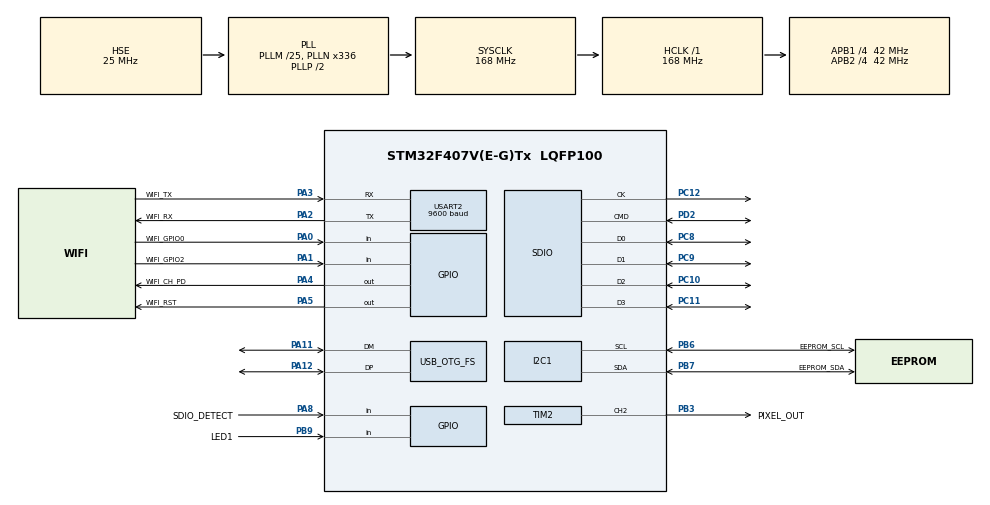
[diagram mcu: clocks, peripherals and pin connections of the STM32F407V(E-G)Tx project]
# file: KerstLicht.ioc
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Dma.Request0=TIM2_CH2/CH4
Dma.Request1=USART2_RX
Dma.TIM2_CH2/CH4.0.Direction=DMA_MEMORY_TO_PERIPH
Dma.TIM2_CH2/CH4.0.FIFOMode=DMA_FIFOMODE_DISABLE
Dma.TIM2_CH2/CH4.0.Instance=DMA1_Stream6
Dma.TIM2_CH2/CH4.0.MemDataAlignment=DMA_MDATAALIGN_WORD
Dma.TIM2_CH2/CH4.0.MemInc=DMA_MINC_ENABLE
Dma.TIM2_CH2/CH4.0.Mode=DMA_NORMAL
Dma.TIM2_CH2/CH4.0.PeriphDataAlignment=DMA_PDATAALIGN_WORD
Dma.TIM2_CH2/CH4.0.PeriphInc=DMA_PINC_DISABLE
Dma.TIM2_CH2/CH4.0.Priority=DMA_PRIORITY_HIGH
Dma.USART2_RX.1.Direction=DMA_PERIPH_TO_MEMORY
Dma.USART2_RX.1.FIFOMode=DMA_FIFOMODE_ENABLE
Dma.USART2_RX.1.FIFOThreshold=DMA_FIFO_THRESHOLD_FULL
Dma.USART2_RX.1.Instance=DMA1_Stream5
Dma.USART2_RX.1.MemBurst=DMA_MBURST_SINGLE
Dma.USART2_RX.1.MemDataAlignment=DMA_MDATAALIGN_BYTE
Dma.USART2_RX.1.MemInc=DMA_MINC_ENABLE
Dma.USART2_RX.1.Mode=DMA_NORMAL
Dma.USART2_RX.1.PeriphBurst=DMA_PBURST_SINGLE
Dma.USART2_RX.1.PeriphDataAlignment=DMA_PDATAALIGN_BYTE
Dma.USART2_RX.1.PeriphInc=DMA_PINC_DISABLE
Dma.USART2_RX.1.Priority=DMA_PRIORITY_LOW
FATFS.BSP.number=1
FATFS.USE_DMA_CODE_SD=1
FATFS0.BSP.STBoard=false
FATFS0.BSP.api=Unknown
FATFS0.BSP.i2caddr=0
FATFS0.BSP.instance=PA8
FATFS0.BSP.ip=GPIO
FATFS0.BSP.mode=Input
FATFS0.BSP.name=Detect_SDIO
FATFS0.BSP.solution=PA8
FREERTOS.Tasks01=defaultTask,0,128,StartDefaultTask,Default,NULL,Dynamic,NULL,NULL
Mcu.Family=STM32F4
Mcu.Name=STM32F407V(E-G)Tx
Mcu.Package=LQFP100
NVIC.DMA1_Stream5_IRQn=true\:5\:0\:false\:false\:true\:true\:false\:true
NVIC.DMA1_Stream6_IRQn=true\:5\:0\:false\:false\:true\:true\:true\:true
NVIC.OTG_FS_IRQn=true\:6\:0\:true\:false\:true\:true\:true\:true
NVIC.PriorityGroup=NVIC_PRIORITYGROUP_4
NVIC.TIM3_IRQn=true\:0\:0\:false\:false\:true\:false\:false\:true
NVIC.TimeBase=TIM3_IRQn
NVIC.TimeBaseIP=TIM3
NVIC.USART2_IRQn=true\:5\:0\:false\:false\:true\:true\:true\:true
PA0-WKUP.GPIO_Label=WIFI_GPIO0
PA0-WKUP.Signal=GPIO_Input
PA1.GPIO_Label=WIFI_GPIO2
PA1.Signal=GPIO_Input
PA11.Mode=Device_Only
PA11.Signal=USB_OTG_FS_DM
PA12.Mode=Device_Only
PA12.Signal=USB_OTG_FS_DP
PA13.Mode=Serial_Wire
PA13.Signal=SYS_JTMS-SWDIO
PA14.Mode=Serial_Wire
PA14.Signal=SYS_JTCK-SWCLK
PA2.GPIO_Label=WIFI_RX
PA2.Mode=Asynchronous
PA2.Signal=USART2_TX
PA3.GPIO_Label=WIFI_TX
PA3.Mode=Asynchronous
PA3.Signal=USART2_RX
PA4.GPIO_Label=WIFI_CH_PD
PA4.GPIO_ModeDefaultOutputPP=GPIO_MODE_OUTPUT_OD
PA4.GPIO_PuPd=GPIO_PULLUP
PA4.Signal=GPIO_Output
PA5.GPIO_Label=WIFI_RST
PA5.GPIO_ModeDefaultOutputPP=GPIO_MODE_OUTPUT_OD
PA5.GPIO_PuPd=GPIO_PULLUP
PA5.Signal=GPIO_Output
PA8.GPIO_Label=SDIO_DETECT
PA8.Signal=GPIO_Input
PB3.GPIO_Label=PIXEL_OUT
PB3.Signal=S_TIM2_CH2
PB6.GPIO_Label=EEPROM_SCL
PB6.Mode=I2C
PB6.Signal=I2C1_SCL
PB7.GPIO_Label=EEPROM_SDA
PB7.Mode=I2C
PB7.Signal=I2C1_SDA
PB9.GPIO_Label=LED1
PB9.Signal=GPIO_Input
PC10.Mode=SD_4_bits_Wide_bus
PC10.Signal=SDIO_D2
PC11.Mode=SD_4_bits_Wide_bus
PC11.Signal=SDIO_D3
PC12.Mode=SD_4_bits_Wide_bus
PC12.Signal=SDIO_CK
PC14-OSC32_IN.Mode=LSE-External-Oscillator
PC14-OSC32_IN.Signal=RCC_OSC32_IN
PC15-OSC32_OUT.Mode=LSE-External-Oscillator
PC15-OSC32_OUT.Signal=RCC_OSC32_OUT
PC8.Mode=SD_4_bits_Wide_bus
PC8.Signal=SDIO_D0
PC9.Mode=SD_4_bits_Wide_bus
PC9.Signal=SDIO_D1
PD2.Mode=SD_4_bits_Wide_bus
PD2.Signal=SDIO_CMD
PH0-OSC_IN.Mode=HSE-External-Oscillator
PH0-OSC_IN.Signal=RCC_OSC_IN
PH1-OSC_OUT.Mode=HSE-External-Oscillator
PH1-OSC_OUT.Signal=RCC_OSC_OUT
ProjectManager.HeapSize=0x200
ProjectManager.StackSize=0x400
ProjectManager.TargetToolchain=Other Toolchains (GPDSC)
RCC.48MHZClocksFreq_Value=48000000
RCC.AHBFreq_Value=168000000
RCC.APB1CLKDivider=RCC_HCLK_DIV4
RCC.APB1Freq_Value=42000000
RCC.APB1TimFreq_Value=84000000
RCC.APB2CLKDivider=RCC_HCLK_DIV4
RCC.APB2Freq_Value=42000000
RCC.APB2TimFreq_Value=84000000
RCC.CortexFreq_Value=168000000
RCC.HCLKFreq_Value=168000000
RCC.HSE_VALUE=25000000
RCC.HSI_VALUE=16000000
RCC.PLLM=25
RCC.PLLN=336
RCC.PLLQ=7
RCC.RCC_RTC_Clock_Source=RCC_RTCCLKSOURCE_LSE
RCC.RCC_RTC_Clock_SourceVirtual=RCC_RTCCLKSOURCE_LSE
RCC.SYSCLKFreq_VALUE=168000000
RCC.SYSCLKSource=RCC_SYSCLKSOURCE_PLLCLK
RCC.VCOOutputFreq_Value=336000000
SH.S_TIM2_CH2.0=TIM2_CH2,PWM Generation2 CH2
TIM2.Channel-PWM\ Generation2\ CH2=TIM_CHANNEL_2
TIM2.Period=104
USART2.BaudRate=9600
USART2.VirtualMode=VM_ASYNC
USB_DEVICE.CLASS_NAME_FS=CDC
USB_DEVICE.PID_CDC_FS=0x5740
USB_DEVICE.USBD_DEBUG_LEVEL-CDC_FS=3
USB_DEVICE.VID-CDC_FS=0x483
USB_DEVICE.VirtualMode-CDC_FS=Cdc
USB_DEVICE.VirtualModeFS=Cdc_FS
USB_OTG_FS.VirtualMode=Device_Only
VP_CRC_VS_CRC.Mode=CRC_Activate
VP_FATFS_VS_SDIO.Mode=SDIO
VP_FREERTOS_VS_CMSIS_V1.Mode=CMSIS_V1
VP_RNG_VS_RNG.Mode=RNG_Activate
VP_RTC_VS_RTC_Activate.Mode=RTC_Enabled
VP_SYS_VS_tim3.Mode=TIM3
VP_USB_DEVICE_VS_USB_DEVICE_CDC_FS.Mode=CDC_FS
board=custom

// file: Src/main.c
/* USER CODE BEGIN Header */
/**
  ******************************************************************************
  * @file           : main.c
  * @brief          : Main program body
  ******************************************************************************
  * @attention
  *
  * <h2><center>&copy; Copyright (c) 2019 STMicroelectronics.
  * All rights reserved.</center></h2>
  *
  * This software component is licensed by ST under Ultimate Liberty license
  * SLA0044, the "License"; You may not use this file except in compliance with
  * the License. You may obtain a copy of the License at:
  *                             www.st.com/SLA0044
  *
  ******************************************************************************
  */
/* USER CODE END Header */

#include "main.h"
#include "cmsis_os.h"
#include "fatfs.h"
#include "usb_device.h"

CRC_HandleTypeDef hcrc;

I2C_HandleTypeDef hi2c1;

RNG_HandleTypeDef hrng;

RTC_HandleTypeDef hrtc;

SD_HandleTypeDef hsd;

TIM_HandleTypeDef htim2;
DMA_HandleTypeDef hdma_tim2_ch2_ch4;

UART_HandleTypeDef huart2;
DMA_HandleTypeDef hdma_usart2_rx;

osThreadId defaultTaskHandle;

void SystemClock_Config(void);
static void MX_GPIO_Init(void);
static void MX_DMA_Init(void);
static void MX_I2C1_Init(void);
static void MX_RNG_Init(void);
static void MX_RTC_Init(void);
static void MX_SDIO_SD_Init(void);
static void MX_TIM2_Init(void);
static void MX_USART2_UART_Init(void);
static void MX_CRC_Init(void);
void StartDefaultTask(void const * argument);

int main(void)
{
  /* USER CODE BEGIN 1 */
    __disable_irq ();
  /* USER CODE END 1 */

  /* MCU Configuration--------------------------------------------------------*/

  /* Reset of all peripherals, Initializes the Flash interface and the Systick. */
  HAL_Init();

  /* Configure the system clock */
  SystemClock_Config();

  /* Initialize all configured peripherals */
  MX_GPIO_Init();
  MX_DMA_Init();
  MX_I2C1_Init();
  MX_RNG_Init();
  MX_RTC_Init();
  MX_SDIO_SD_Init();
  MX_TIM2_Init();
  MX_USART2_UART_Init();
  MX_CRC_Init();
  /* USER CODE BEGIN 2 */
  __enable_irq ();
  /* USER CODE END 2 */

  /* Create the thread(s) */
  /* definition and creation of defaultTask */
  osThreadDef(defaultTask, StartDefaultTask, osPriorityNormal, 0, 128);
  defaultTaskHandle = osThreadCreate(osThread(defaultTask), NULL);

  /* Start scheduler */
  osKernelStart();

  /* We should never get here as control is now taken by the scheduler */

  /* Infinite loop */
  while (1)
  {

  }
}

void SystemClock_Config(void)
{
  RCC_OscInitTypeDef RCC_OscInitStruct = {0};
  RCC_ClkInitTypeDef RCC_ClkInitStruct = {0};
  RCC_PeriphCLKInitTypeDef PeriphClkInitStruct = {0};

  /** Configure the main internal regulator output voltage
  */
  __HAL_RCC_PWR_CLK_ENABLE();
  __HAL_PWR_VOLTAGESCALING_CONFIG(PWR_REGULATOR_VOLTAGE_SCALE1);
  /** Initializes the CPU, AHB and APB busses clocks
  */
  RCC_OscInitStruct.OscillatorType = RCC_OSCILLATORTYPE_HSE|RCC_OSCILLATORTYPE_LSE;
  RCC_OscInitStruct.HSEState = RCC_HSE_ON;
  RCC_OscInitStruct.LSEState = RCC_LSE_ON;
  RCC_OscInitStruct.PLL.PLLState = RCC_PLL_ON;
  RCC_OscInitStruct.PLL.PLLSource = RCC_PLLSOURCE_HSE;
  RCC_OscInitStruct.PLL.PLLM = 25;
  RCC_OscInitStruct.PLL.PLLN = 336;
  RCC_OscInitStruct.PLL.PLLP = RCC_PLLP_DIV2;
  RCC_OscInitStruct.PLL.PLLQ = 7;
  if (HAL_RCC_OscConfig(&RCC_OscInitStruct) != HAL_OK)
  {
    Error_Handler();
  }
  /** Initializes the CPU, AHB and APB busses clocks
  */
  RCC_ClkInitStruct.ClockType = RCC_CLOCKTYPE_HCLK|RCC_CLOCKTYPE_SYSCLK
                              |RCC_CLOCKTYPE_PCLK1|RCC_CLOCKTYPE_PCLK2;
  RCC_ClkInitStruct.SYSCLKSource = RCC_SYSCLKSOURCE_PLLCLK;
  RCC_ClkInitStruct.AHBCLKDivider = RCC_SYSCLK_DIV1;
  RCC_ClkInitStruct.APB1CLKDivider = RCC_HCLK_DIV4;
  RCC_ClkInitStruct.APB2CLKDivider = RCC_HCLK_DIV4;

  if (HAL_RCC_ClockConfig(&RCC_ClkInitStruct, FLASH_LATENCY_5) != HAL_OK)
  {
    Error_Handler();
  }
  PeriphClkInitStruct.PeriphClockSelection = RCC_PERIPHCLK_RTC;
  PeriphClkInitStruct.RTCClockSelection = RCC_RTCCLKSOURCE_LSE;
  if (HAL_RCCEx_PeriphCLKConfig(&PeriphClkInitStruct) != HAL_OK)
  {
    Error_Handler();
  }
}

static void MX_CRC_Init(void)
{

  hcrc.Instance = CRC;
  if (HAL_CRC_Init(&hcrc) != HAL_OK)
  {
    Error_Handler();
  }

}

static void MX_I2C1_Init(void)
{

  hi2c1.Instance = I2C1;
  hi2c1.Init.ClockSpeed = 100000;
  hi2c1.Init.DutyCycle = I2C_DUTYCYCLE_2;
  hi2c1.Init.OwnAddress1 = 0;
  hi2c1.Init.AddressingMode = I2C_ADDRESSINGMODE_7BIT;
  hi2c1.Init.DualAddressMode = I2C_DUALADDRESS_DISABLE;
  hi2c1.Init.OwnAddress2 = 0;
  hi2c1.Init.GeneralCallMode = I2C_GENERALCALL_DISABLE;
  hi2c1.Init.NoStretchMode = I2C_NOSTRETCH_DISABLE;
  if (HAL_I2C_Init(&hi2c1) != HAL_OK)
  {
    Error_Handler();
  }

}

static void MX_RNG_Init(void)
{

  hrng.Instance = RNG;
  if (HAL_RNG_Init(&hrng) != HAL_OK)
  {
    Error_Handler();
  }

}

static void MX_RTC_Init(void)
{

  /** Initialize RTC Only
  */
  hrtc.Instance = RTC;
  hrtc.Init.HourFormat = RTC_HOURFORMAT_24;
  hrtc.Init.AsynchPrediv = 127;
  hrtc.Init.SynchPrediv = 255;
  hrtc.Init.OutPut = RTC_OUTPUT_DISABLE;
  hrtc.Init.OutPutPolarity = RTC_OUTPUT_POLARITY_HIGH;
  hrtc.Init.OutPutType = RTC_OUTPUT_TYPE_OPENDRAIN;
  if (HAL_RTC_Init(&hrtc) != HAL_OK)
  {
    Error_Handler();
  }

}

static void MX_SDIO_SD_Init(void)
{

  hsd.Instance = SDIO;
  hsd.Init.ClockEdge = SDIO_CLOCK_EDGE_RISING;
  hsd.Init.ClockBypass = SDIO_CLOCK_BYPASS_DISABLE;
  hsd.Init.ClockPowerSave = SDIO_CLOCK_POWER_SAVE_DISABLE;
  hsd.Init.BusWide = SDIO_BUS_WIDE_1B;
  hsd.Init.HardwareFlowControl = SDIO_HARDWARE_FLOW_CONTROL_DISABLE;
  hsd.Init.ClockDiv = 0;

}

static void MX_TIM2_Init(void)
{

  TIM_MasterConfigTypeDef sMasterConfig = {0};
  TIM_OC_InitTypeDef sConfigOC = {0};

  htim2.Instance = TIM2;
  htim2.Init.Prescaler = 0;
  htim2.Init.CounterMode = TIM_COUNTERMODE_UP;
  htim2.Init.Period = 104;
  htim2.Init.ClockDivision = TIM_CLOCKDIVISION_DIV1;
  htim2.Init.AutoReloadPreload = TIM_AUTORELOAD_PRELOAD_DISABLE;
  if (HAL_TIM_PWM_Init(&htim2) != HAL_OK)
  {
    Error_Handler();
  }
  sMasterConfig.MasterOutputTrigger = TIM_TRGO_RESET;
  sMasterConfig.MasterSlaveMode = TIM_MASTERSLAVEMODE_DISABLE;
  if (HAL_TIMEx_MasterConfigSynchronization(&htim2, &sMasterConfig) != HAL_OK)
  {
    Error_Handler();
  }
  sConfigOC.OCMode = TIM_OCMODE_PWM1;
  sConfigOC.Pulse = 0;
  sConfigOC.OCPolarity = TIM_OCPOLARITY_HIGH;
  sConfigOC.OCFastMode = TIM_OCFAST_DISABLE;
  if (HAL_TIM_PWM_ConfigChannel(&htim2, &sConfigOC, TIM_CHANNEL_2) != HAL_OK)
  {
    Error_Handler();
  }
  HAL_TIM_MspPostInit(&htim2);

}

static void MX_USART2_UART_Init(void)
{

  huart2.Instance = USART2;
  huart2.Init.BaudRate = 9600;
  huart2.Init.WordLength = UART_WORDLENGTH_8B;
  huart2.Init.StopBits = UART_STOPBITS_1;
  huart2.Init.Parity = UART_PARITY_NONE;
  huart2.Init.Mode = UART_MODE_TX_RX;
  huart2.Init.HwFlowCtl = UART_HWCONTROL_NONE;
  huart2.Init.OverSampling = UART_OVERSAMPLING_16;
  if (HAL_UART_Init(&huart2) != HAL_OK)
  {
    Error_Handler();
  }

}

static void MX_DMA_Init(void)
{

  /* DMA controller clock enable */
  __HAL_RCC_DMA1_CLK_ENABLE();

  /* DMA interrupt init */
  /* DMA1_Stream5_IRQn interrupt configuration */
  HAL_NVIC_SetPriority(DMA1_Stream5_IRQn, 5, 0);
  HAL_NVIC_EnableIRQ(DMA1_Stream5_IRQn);
  /* DMA1_Stream6_IRQn interrupt configuration */
  HAL_NVIC_SetPriority(DMA1_Stream6_IRQn, 5, 0);
  HAL_NVIC_EnableIRQ(DMA1_Stream6_IRQn);

}

static void MX_GPIO_Init(void)
{
  GPIO_InitTypeDef GPIO_InitStruct = {0};

  /* GPIO Ports Clock Enable */
  __HAL_RCC_GPIOC_CLK_ENABLE();
  __HAL_RCC_GPIOH_CLK_ENABLE();
  __HAL_RCC_GPIOA_CLK_ENABLE();
  __HAL_RCC_GPIOD_CLK_ENABLE();
  __HAL_RCC_GPIOB_CLK_ENABLE();

  /*Configure GPIO pin Output Level */
  HAL_GPIO_WritePin(GPIOA, WIFI_CH_PD_Pin|WIFI_RST_Pin, GPIO_PIN_SET);

  /*Configure GPIO pins : WIFI_GPIO0_Pin WIFI_GPIO2_Pin SDIO_DETECT_Pin */
  GPIO_InitStruct.Pin = WIFI_GPIO0_Pin|WIFI_GPIO2_Pin|SDIO_DETECT_Pin;
  GPIO_InitStruct.Mode = GPIO_MODE_INPUT;
  GPIO_InitStruct.Pull = GPIO_NOPULL;
  HAL_GPIO_Init(GPIOA, &GPIO_InitStruct);

  /*Configure GPIO pins : WIFI_CH_PD_Pin WIFI_RST_Pin */
  GPIO_InitStruct.Pin = WIFI_CH_PD_Pin|WIFI_RST_Pin;
  GPIO_InitStruct.Mode = GPIO_MODE_OUTPUT_OD;
  GPIO_InitStruct.Pull = GPIO_PULLUP;
  GPIO_InitStruct.Speed = GPIO_SPEED_FREQ_LOW;
  HAL_GPIO_Init(GPIOA, &GPIO_InitStruct);

  /*Configure GPIO pin : LED1_Pin */
  GPIO_InitStruct.Pin = LED1_Pin;
  GPIO_InitStruct.Mode = GPIO_MODE_INPUT;
  GPIO_InitStruct.Pull = GPIO_NOPULL;
  HAL_GPIO_Init(LED1_GPIO_Port, &GPIO_InitStruct);

}

void StartDefaultTask(void const * argument)
{
  /* init code for USB_DEVICE */
  MX_USB_DEVICE_Init();

  /* init code for FATFS */
  MX_FATFS_Init();
  for(;;)
  {
    osDelay(1);
  }
}

void HAL_TIM_PeriodElapsedCallback(TIM_HandleTypeDef *htim)
{
  if (htim->Instance == TIM3) {
    HAL_IncTick();
  }
}

void Error_Handler(void)
{
  /* USER CODE BEGIN Error_Handler_Debug */
  /* User can add his own implementation to report the HAL error return state */
    for (;;) {
        osDelay (1);
    }
  /* USER CODE END Error_Handler_Debug */
}

/************************ (C) COPYRIGHT STMicroelectronics *****END OF FILE****/
